VERSION ""

NS_ :

BS_:

BU_: RFHM BCM Occupant_Restraint_Controller Active_Vibration_Cancellation Steering_Column EPS Occupant_Classification Cluster Park_Assist_Module TCU Electronic_Shifter_Module ECM ABS XXX
VAL_TABLE_ Break_Press_Status 1 "Pressed" 0 "Not Pressed" ;

BO_ 1665 NEW_MSG_1: 8 XXX

BO_ 545 NEW_MSG_2: 8 XXX

BO_ 261 NEW_MSG_3: 8 XXX
 SG_ NEW_SIGNAL_1 : 15|2@0+ (1,0) [0|3] ""  XXX
 SG_ NEW_SIGNAL_2 : 0|4@1+ (1,0) [0|15] ""  XXX

BO_ 35 C3_Steering_Column_msg1: 8 Steering_Column

BO_ 133 C2_Transmission_Control_msg1: 8 TCU

BO_ 55 C2_Transmission_Control_msg4: 8 TCU

BO_ 119 BCM_Power_Mode: 1 BCM
 SG_ Power_Mode : 7|4@0+ (1,0) [0|15] "" Vector__XXX

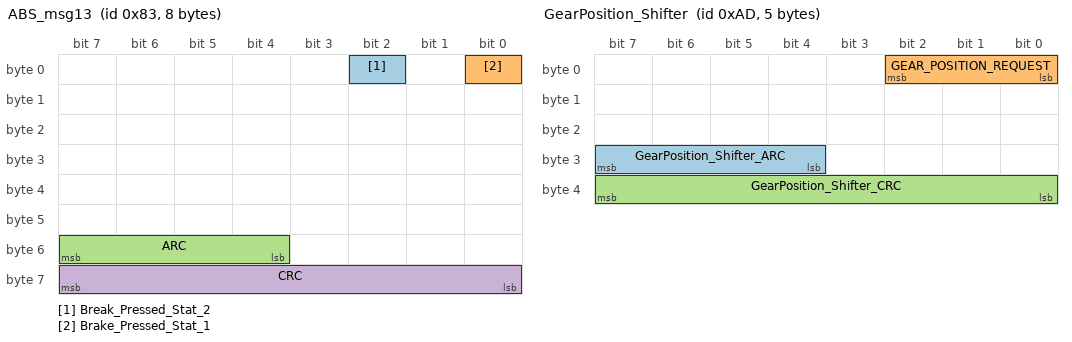
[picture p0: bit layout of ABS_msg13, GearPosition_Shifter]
BO_ 131 ABS_msg13: 8 ABS
 SG_ Break_Pressed_Stat_2 : 2|1@0+ (1,0) [0|1] "" Vector__XXX
 SG_ Brake_Pressed_Stat_1 : 0|1@0+ (1,0) [0|1] ""  XXX
 SG_ ARC : 55|4@0+ (1,0) [0|15] ""  XXX
 SG_ CRC : 63|8@0+ (1,0) [0|255] ""  XXX

BO_ 177 C3_Steering_Column_msg2: 3 Steering_Column

BO_ 213 C5_Antilock_braking_system_msg4: 8 ABS

BO_ 808 C8_Body_Control_msg49: 8 BCM
 SG_ NEW_SIGNAL_1 : 5|20@0+ (1,0) [0|1048575] ""  XXX

BO_ 173 GearPosition_Shifter: 5 Electronic_Shifter_Module
 SG_ GearPosition_Shifter_ARC : 31|4@0+ (1,0) [0|15] ""  XXX
 SG_ GEAR_POSITION_REQUEST : 0|3@1+ (1,0) [0|7] ""  XXX
 SG_ GearPosition_Shifter_CRC : 32|8@1+ (1,0) [0|255] ""  XXX

BO_ 1033 C6_Electronic_Shifter_msg1: 8 Electronic_Shifter_Module

BO_ 973 C2_Cluster_msg1: 8 Cluster

BO_ 906 C8_Body_Control_msg1: 8 BCM

BO_ 792 C3_Steering_Column_msg3: 8 Steering_Column

BO_ 1059 C3_Steering_Column_msg4: 8 Steering_Column

BO_ 938 C2_Cluster_msg2: 8 Cluster

BO_ 673 C2_Cluster_msg3: 8 Cluster

BO_ 635 C2_Cluster_msg4: 8 Cluster

BO_ 939 C2_Cluster_msg5: 8 Cluster

BO_ 634 C2_Cluster_msg6: 8 Cluster

BO_ 940 C2_Cluster_msg7: 8 Cluster

BO_ 941 C2_Cluster_msg8: 8 Cluster

BO_ 942 C2_Cluster_msg9: 8 Cluster

BO_ 943 C2_Cluster_msg10: 8 Cluster

BO_ 503 C2_Cluster_msg11: 8 Cluster

BO_ 1026 C2_Cluster_msg12: 8 Cluster

BO_ 754 C2_Cluster_msg13: 8 Cluster

BO_ 464 C7_Occupant_Restraint_msg2: 8 Occupant_Restraint_Controller

BO_ 43 C7_Occupant_Restraint_msg1: 8 Occupant_Restraint_Controller

BO_ 996 C8_Body_Control_msg2: 8 BCM

BO_ 910 C8_Body_Control_msg3: 8 BCM

BO_ 995 C8_Body_Control_msg5: 8 BCM

BO_ 926 C8_Body_Control_msg6: 3 BCM

BO_ 1002 C8_Body_Control_msg7: 8 BCM

BO_ 1008 C8_Body_Control_msg9: 8 BCM

BO_ 1098 C8_Body_Control_msg10: 8 BCM

BO_ 948 C8_Body_Control_msg11: 8 BCM

BO_ 962 C8_Body_Control_msg12: 8 BCM

BO_ 1009 C8_Body_Control_msg13: 8 BCM

BO_ 1100 C8_Body_Control_msg14: 8 BCM

BO_ 1010 C8_Body_Control_msg15: 8 BCM

BO_ 1015 C8_Body_Control_msg16: 8 BCM

BO_ 984 C8_Body_Control_msg17: 8 BCM

BO_ 1011 C8_Body_Control_msg18: 8 BCM

BO_ 983 C8_Body_Control_msg19: 8 BCM

BO_ 1012 C8_Body_Control_msg20: 8 BCM

BO_ 1013 C8_Body_Control_msg21: 8 BCM

BO_ 981 C8_Body_Control_msg25: 8 BCM

BO_ 979 C8_Body_Control_msg23: 8 BCM

BO_ 980 C8_Body_Control_msg24: 8 BCM

BO_ 982 C8_Body_Control_msg25: 8 BCM

BO_ 1014 C8_Body_Control_msg26: 8 BCM

BO_ 706 C8_Body_Control_msg27: 8 BCM

BO_ 709 C8_Body_Control_msg28: 8 BCM

BO_ 710 C8_Body_Control_msg29: 8 BCM

BO_ 897 C8_Body_Control_msg30: 8 BCM

BO_ 613 C8_Body_Control_msg31: 8 BCM

BO_ 937 C8_Body_Control_msg32: 8 BCM

BO_ 607 C8_Body_Control_msg33: 8 BCM

BO_ 605 C8_Body_Control_msg34: 8 BCM

BO_ 1003 C8_Body_Control_msg35: 8 BCM

BO_ 689 C8_Body_Control_msg36: 4 BCM

BO_ 609 C8_Body_Control_msg37: 8 BCM

BO_ 663 C8_Body_Control_msg38: 8 BCM

BO_ 557 C8_Body_Control_msg39: 8 BCM

BO_ 641 C8_Body_Control_msg36: 8 BCM

BO_ 856 C8_Body_Control_msg41: 8 BCM

BO_ 643 C8_Body_Control_msg42: 8 BCM

BO_ 860 C8_Body_Control_msg43: 8 BCM

BO_ 969 C8_Body_Control_msg44: 4 BCM

BO_ 657 C8_Body_Control_msg45: 8 BCM

BO_ 649 C8_Body_Control_msg46: 8 BCM

BO_ 650 C8_Body_Control_msg47: 8 BCM

BO_ 623 C8_Body_Control_msg1: 8 BCM

BO_ 848 C8_Body_Control_msg50: 8 BCM

BO_ 818 C8_Body_Control_msg51: 8 BCM

BO_ 752 C8_Body_Control_msg52: 2 BCM

BO_ 1000 C8_Body_Control_msg53: 8 BCM

BO_ 456 C8_Body_Control_msg54: 8 BCM

BO_ 560 C8_Body_Control_msg55: 8 BCM

BO_ 584 C8_Body_Control_msg56: 8 BCM

BO_ 1025 C8_Body_Control_msg57: 8 BCM

BO_ 307 C8_Body_Control_msg58: 8 BCM

BO_ 299 C8_Body_Control_msg59: 8 BCM

BO_ 319 C8_Body_Control_msg60: 8 BCM

BO_ 720 C8_Body_Control_msg61: 8 BCM

BO_ 155 C8_Body_Control_msg63: 8 BCM

BO_ 656 C9_Radio_Frequency_Hub_msg1: 4 RFHM

BO_ 679 C9_Radio_Frequency_Hub_msg2: 8 RFHM

BO_ 773 C9_Radio_Frequency_Hub_msg3: 8 RFHM

BO_ 1024 C9_Radio_Frequency_Hub_msg4: 8 RFHM

BO_ 297 C9_Radio_Frequency_Hub_msg5: 4 RFHM

BO_ 448 C9_Radio_Frequency_Hub_msg6: 8 RFHM

BO_ 502 C10_Park_Assist_msg1: 8 Park_Assist_Module

BO_ 489 C10_Park_Assist_msg2: 8 Park_Assist_Module

BO_ 825 C10_Park_Assist_msg3: 2 Park_Assist_Module

BO_ 491 C10_Park_Assist_msg4: 8 Park_Assist_Module

BO_ 169 C10_Park_Assist_msg5: 8 Park_Assist_Module

BO_ 601 C12_Occupant_Classification_msg1: 8 Occupant_Classification

BO_ 293 C2_Transmission_Control_msg1: 3 TCU

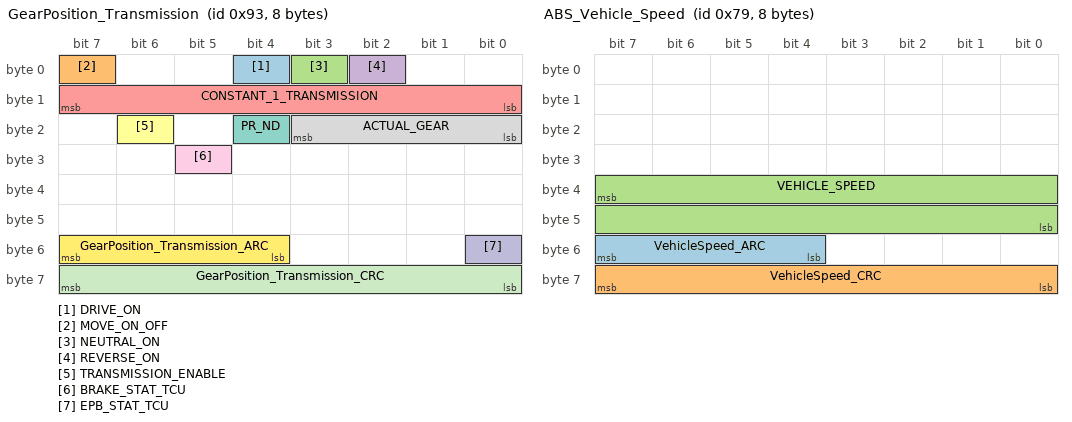
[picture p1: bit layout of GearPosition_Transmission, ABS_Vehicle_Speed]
BO_ 147 GearPosition_Transmission: 8 TCU
 SG_ DRIVE_ON : 4|1@0+ (1,0) [0|1] ""  XXX
 SG_ MOVE_ON_OFF : 7|1@0+ (1,0) [0|1] ""  XXX
 SG_ NEUTRAL_ON : 3|1@0+ (1,0) [0|1] ""  XXX
 SG_ REVERSE_ON : 2|1@0+ (1,0) [0|1] ""  XXX
 SG_ CONSTANT_1_TRANSMISSION : 15|8@0+ (1,0) [0|255] ""  XXX
 SG_ TRANSMISSION_ENABLE : 22|1@0+ (1,0) [0|1] ""  XXX
 SG_ PR_ND : 20|1@0+ (1,0) [0|1] ""  XXX
 SG_ ACTUAL_GEAR : 16|4@1+ (1,0) [0|15] ""  XXX
 SG_ BRAKE_STAT_TCU : 29|1@0+ (1,0) [0|1] ""  XXX
 SG_ EPB_STAT_TCU : 48|1@0+ (1,0) [0|1] ""  XXX
 SG_ GearPosition_Transmission_CRC : 63|8@0+ (1,0) [0|255] ""  XXX
 SG_ GearPosition_Transmission_ARC : 55|4@0+ (1,0) [0|15] ""  XXX

BO_ 149 C2_Transmission_Control_msg5: 7 TCU

BO_ 171 C2_Transmission_Control_msg6: 8 TCU

BO_ 179 C2_Transmission_Control_msg7: 8 TCU

BO_ 1050 C3_Eps_msg1: 8 EPS

BO_ 296 C3_Eps_msg1: 8 EPS

BO_ 164 C3_Eps_msg3: 8 EPS

BO_ 49 C3_Eps_msg4: 8 EPS

BO_ 875 C4_Active_Vibration_Cancellation: 2 Active_Vibration_Cancellation

BO_ 1031 ABS_NM_msg: 8 ABS

BO_ 421 C5_Antilock_braking_system_msg2: 8 ABS

BO_ 221 C5_Antilock_braking_system_msg3: 8 ABS

BO_ 135 C5_Antilock_braking_system_msg5: 8 ABS

BO_ 137 C5_Antilock_braking_system_msg6: 8 ABS

BO_ 167 C5_Antilock_braking_system_msg8: 8 ABS

BO_ 47 ABS_msg9: 8 ABS
 SG_ Brake_Pedal_Voltage : 39|16@0+ (0.0051,0) [0|334.2285] ""  XXX

BO_ 113 C5_Antilock_braking_system_msg10: 8 ABS

BO_ 121 ABS_Vehicle_Speed: 8 ABS
 SG_ VehicleSpeed_ARC : 55|4@0+ (1,0) [0|15] ""  XXX
 SG_ VehicleSpeed_CRC : 63|8@0+ (1,0) [0|255] ""  XXX
 SG_ VEHICLE_SPEED : 39|16@0+ (0.00483,0) [0|316.6] "MPH"  XXX

BO_ 127 C5_Antilock_braking_system_msg12: 8 ABS

BO_ 633 ECM_msg1: 8 ECM
 SG_ Engine_Oil_Life : 15|8@0+ (1,0) [0|255] ""  XXX

BO_ 347 C6_Powertrain_Control_msg2: 8 ECM

BO_ 676 C6_Powertrain_Control_msg3: 8 ECM

BO_ 343 C6_Powertrain_Control_msg4: 8 ECM

BO_ 323 C6_Powertrain_Control_msg5: 8 ECM

BO_ 317 C6_Powertrain_Control_msg6: 8 ECM

BO_ 289 C6_Powertrain_Control_msg7: 5 ECM

BO_ 993 C6_Powertrain_Control_msg8: 7 ECM

BO_ 334 C6_Powertrain_Control_msg9: 8 ECM

BO_ 129 C6_Powertrain_Control_msg10: 8 ECM

BO_ 125 C6_Powertrain_Control_msg11: 8 ECM

BO_ 311 C6_Powertrain_Control_msg12: 8 ECM

BO_ 333 C6_Powertrain_Control_msg13: 8 ECM

BO_ 181 ECM_msg14: 8 ECM
 SG_ Engine_Speed_DIS : 23|16@0+ (1,0) [0|65535] ""  XXX

BO_ 295 C6_Powertrain_Control_msg15: 8 ECM

BO_ 992 C6_Powertrain_Control_msg16: 8 ECM

BO_ 53 C6_Powertrain_Control_msg17: 8 ECM

BO_ 123 C6_Powertrain_Control_msg18: 7 ECM

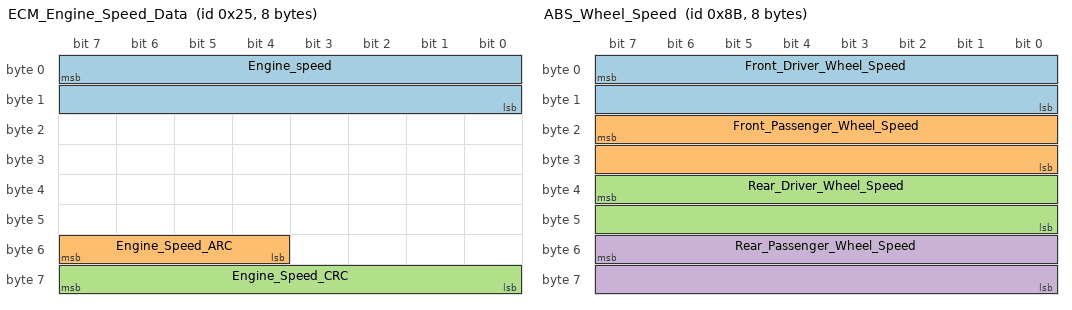
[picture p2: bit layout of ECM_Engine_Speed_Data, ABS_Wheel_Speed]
BO_ 37 ECM_Engine_Speed_Data: 8 ECM
 SG_ Engine_speed : 7|16@0+ (1,0) [0|65535] ""  XXX
 SG_ Engine_Speed_ARC : 55|4@0+ (1,0) [0|15] ""  XXX
 SG_ Engine_Speed_CRC : 63|8@0+ (1,0) [0|255] ""  XXX

BO_ 157 ECM_msg20: 8 ECM

BO_ 39 C6_Powertrain_Control_msg21: 8 ECM

BO_ 139 ABS_Wheel_Speed: 8 ABS
 SG_ Front_Driver_Wheel_Speed : 7|16@0+ (1,0) [0|65535] ""  XXX
 SG_ Front_Passenger_Wheel_Speed : 23|16@0+ (1,0) [0|65535] ""  XXX
 SG_ Rear_Driver_Wheel_Speed : 39|16@0+ (1,0) [0|65535] ""  XXX
 SG_ Rear_Passenger_Wheel_Speed : 55|16@0+ (1,0) [0|65535] ""  XXX

BO_ 517 ECM_Immobilizer_msg: 8 ECM
 SG_ Immobilizer_Auth : 7|8@0+ (1,0) [0|255] ""  XXX

CM_ BO_ 119 "BCM Powermode status message";
BA_DEF_  "BusType" STRING ;
BA_DEF_ BO_  "ON_C" ENUM  "NO","YES";
BA_DEF_ BU_  "ILUsed" ENUM  "No","Yes";
BA_DEF_ BU_  "NodeLayerModules" STRING ;
BA_DEF_  "Status" ENUM  "DRAFT","RELEASE";
BA_DEF_ BO_  "GenMsgCycleTime" INT 0 0;
BA_DEF_ BO_  "GenMsgSendType" ENUM  "Cyclic","NotUsed","NotUsed","NotUsed","NotUsed","NotUsed","NotUsed","IfActive","NoMsgSendType","NotUsed";
BA_DEF_ SG_  "GenSigSendType" ENUM  "Cyclic","OnWrite","OnWriteWithRepetition","OnChange","OnChangeWithRepetition","IfActive","IfActiveWithRepetition","NoSigSendType","NotUsed","NotUsed","NotUsed","NotUsed","NotUsed";
BA_DEF_  "Baudrate" INT 0 1000000;
BA_DEF_  "Manufacturer" STRING ;
BA_DEF_ BO_  "GenMsgILSupport" ENUM  "No","Yes";
BA_DEF_ BU_  "BusConnection4" ENUM  "NoBusConnection","B-CAN","C-CAN","PT-CAN","INV-CAN";
BA_DEF_ BU_  "BusConnection3" ENUM  "NoBusConnection","B-CAN","C-CAN","PT-CAN","INV-CAN";
BA_DEF_ BU_  "BusConnection2" ENUM  "NoBusConnection","B-CAN","C-CAN","PT-CAN","INV-CAN","SW-CAN";
BA_DEF_ BU_  "BusConnection1" ENUM  "NoBusConnection","B-CAN","C-CAN","PT-CAN","INV-CAN","SW-CAN";
BA_DEF_DEF_  "BusType" "";
BA_DEF_DEF_  "ON_C" "NO";
BA_DEF_DEF_  "ILUsed" "Yes";
BA_DEF_DEF_  "NodeLayerModules" "CANoeILNLVector.dll";
BA_DEF_DEF_  "Status" "DRAFT";
BA_DEF_DEF_  "GenMsgCycleTime" 0;
BA_DEF_DEF_  "GenMsgSendType" "NoMsgSendType";
BA_DEF_DEF_  "GenSigSendType" "NoSigSendType";
BA_DEF_DEF_  "Baudrate" 500000;
BA_DEF_DEF_  "Manufacturer" "KARMA AUTOMOTIVE LLC";
BA_DEF_DEF_  "GenMsgILSupport" "Yes";
BA_DEF_DEF_  "BusConnection4" "NoBusConnection";
BA_DEF_DEF_  "BusConnection3" "NoBusConnection";
BA_DEF_DEF_  "BusConnection2" "NoBusConnection";
BA_DEF_DEF_  "BusConnection1" "NoBusConnection";
BA_ "BusType" "CAN";
BA_ "GenMsgCycleTime" BO_ 119 20;
BA_ "GenMsgSendType" BO_ 119 0;
BA_ "ON_C" BO_ 131 1;
BA_ "GenMsgCycleTime" BO_ 131 20;
BA_ "GenMsgSendType" BO_ 131 0;
BA_ "GenSigSendType" SG_ 131 Break_Pressed_Stat_2 0;
BA_ "GenSigSendType" SG_ 131 Brake_Pressed_Stat_1 0;
VAL_ 119 Power_Mode 19 "RPC_ACTIVE" 5 "PROP_READY" 4 "RUN" 3 "ACC" 1 "OFF" ;
VAL_ 131 Break_Pressed_Stat_2 1 "Pressed" 0 "Not Pressed" ;
VAL_ 131 Brake_Pressed_Stat_1 1 "Pressed" 0 "Not Pressed" ;
VAL_ 173 GEAR_POSITION_REQUEST 4 "Drive" 3 "Neutral" 2 "Reverse" 1 "Park" 0 "NA" ;
VAL_ 147 DRIVE_ON 1 "True" 0 "False" ;
VAL_ 147 MOVE_ON_OFF 1 "STOP" 0 "MOVE" ;
VAL_ 147 NEUTRAL_ON 1 "True" 0 "False" ;
VAL_ 147 REVERSE_ON 1 "True" 0 "False" ;
VAL_ 147 TRANSMISSION_ENABLE 1 "1" 0 "FALSE" ;
VAL_ 147 PR_ND 1 "GEAR ON PR" 0 "GEAR ON ND" ;
VAL_ 147 ACTUAL_GEAR 14 "NEUTRAL" 4 "DRIVE" 2 "REVERSE" 0 "PARK" ;
VAL_ 147 BRAKE_STAT_TCU 1 "PRESSED" 0 "NOT PRESSED" ;
VAL_ 147 EPB_STAT_TCU 1 "APPLIED" 0 "RELEASED" ;
